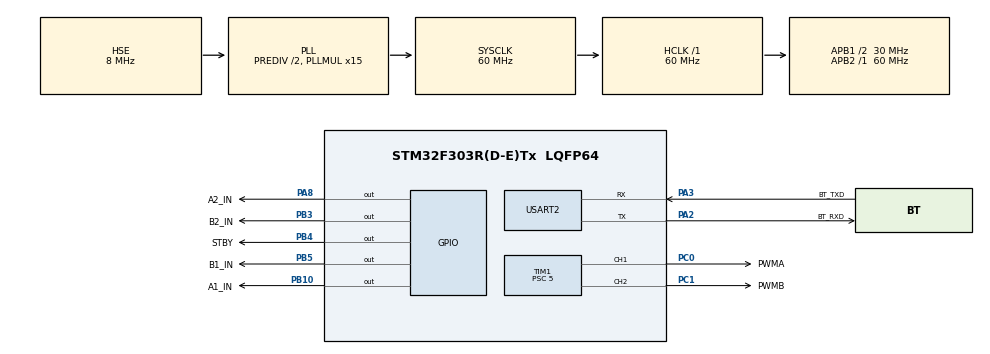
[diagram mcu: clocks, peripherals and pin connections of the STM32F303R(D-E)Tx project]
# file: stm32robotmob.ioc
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Mcu.Family=STM32F3
Mcu.Name=STM32F303R(D-E)Tx
Mcu.Package=LQFP64
NVIC.PriorityGroup=NVIC_PRIORITYGROUP_0
PA2.GPIO_Label=BT_RXD
PA2.Mode=Asynchronous
PA2.Signal=USART2_TX
PA3.GPIO_Label=BT_TXD
PA3.Mode=Asynchronous
PA3.Signal=USART2_RX
PA8.GPIO_Label=A2_IN
PA8.Signal=GPIO_Output
PB10.GPIO_Label=A1_IN
PB10.Signal=GPIO_Output
PB3.GPIO_Label=B2_IN
PB3.Signal=GPIO_Output
PB4.GPIO_Label=STBY
PB4.Signal=GPIO_Output
PB5.GPIO_Label=B1_IN
PB5.Signal=GPIO_Output
PC0.GPIO_Label=PWMA
PC0.Signal=S_TIM1_CH1
PC1.GPIO_Label=PWMB
PC1.Signal=S_TIM1_CH2
PF0-OSC_IN.Mode=HSE-External-Oscillator
PF0-OSC_IN.Signal=RCC_OSC_IN
PF1-OSC_OUT.Mode=HSE-External-Oscillator
PF1-OSC_OUT.Signal=RCC_OSC_OUT
ProjectManager.HeapSize=0x200
ProjectManager.StackSize=0x400
ProjectManager.TargetToolchain=STM32CubeIDE
RCC.AHBFreq_Value=60000000
RCC.APB1CLKDivider=RCC_HCLK_DIV2
RCC.APB1Freq_Value=30000000
RCC.APB1TimFreq_Value=60000000
RCC.APB2Freq_Value=60000000
RCC.APB2TimFreq_Value=60000000
RCC.CortexFreq_Value=60000000
RCC.HCLKFreq_Value=60000000
RCC.HSE_VALUE=8000000
RCC.HSI_VALUE=8000000
RCC.LSE_VALUE=32768
RCC.PLLDivider=RCC_PREDIV_DIV2
RCC.PLLM=8
RCC.PLLMUL=RCC_PLL_MUL15
RCC.PLLN=336
RCC.PLLP=RCC_PLLP_DIV4
RCC.PLLQ=7
RCC.PLLSourceVirtual=RCC_PLLSOURCE_HSE
RCC.RCC_PLLsource_Clock_Source_FROM_HSE=RCC_HSE_PREDIV_DIV2
RCC.SYSCLKFreq_VALUE=60000000
RCC.SYSCLKSourceVirtual=RCC_SYSCLKSOURCE_PLLCLK
RCC.USBFreq_Value=60000000
SH.S_TIM1_CH1.0=TIM1_CH1,PWM Generation1 CH1
SH.S_TIM1_CH2.0=TIM1_CH2,PWM Generation2 CH2
TIM1.AutoReloadPreload=TIM_AUTORELOAD_PRELOAD_ENABLE
TIM1.Channel-PWM\ Generation1\ CH1=TIM_CHANNEL_1
TIM1.Channel-PWM\ Generation2\ CH2=TIM_CHANNEL_2
TIM1.Period=59
TIM1.Prescaler=5
USART2.VirtualMode-Asynchronous=VM_ASYNC
board=NUCLEO-F303RE

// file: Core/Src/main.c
/* USER CODE BEGIN Header */
/**
  ******************************************************************************
  * @file           : main.c
  * @brief          : Main program body
  ******************************************************************************
  * @attention
  *
  * <h2><center>&copy; Copyright (c) 2022 STMicroelectronics.
  * All rights reserved.</center></h2>
  *
  * This software component is licensed by ST under BSD 3-Clause license,
  * the "License"; You may not use this file except in compliance with the
  * License. You may obtain a copy of the License at:
  *                        opensource.org/licenses/BSD-3-Clause
  *
  ******************************************************************************
  */
/* USER CODE END Header */
#include "main.h"
#include "tim.h"
#include "usart.h"
#include "gpio.h"

/* USER CODE BEGIN Includes */
#include "encontrol.h"
/* USER CODE END Includes */

void SystemClock_Config(void);

int main(void)
{

  /* MCU Configuration--------------------------------------------------------*/

  /* Reset of all peripherals, Initializes the Flash interface and the Systick. */
  HAL_Init();

  /* Configure the system clock */
  SystemClock_Config();

  /* Initialize all configured peripherals */
  MX_GPIO_Init();
  MX_TIM1_Init();
  MX_USART2_UART_Init();

  /* Infinite loop */
  while (1)
  {

  }
}

void SystemClock_Config(void)
{
  RCC_OscInitTypeDef RCC_OscInitStruct = {0};
  RCC_ClkInitTypeDef RCC_ClkInitStruct = {0};
  RCC_PeriphCLKInitTypeDef PeriphClkInit = {0};

  /** Initializes the RCC Oscillators according to the specified parameters
  * in the RCC_OscInitTypeDef structure.
  */
  RCC_OscInitStruct.OscillatorType = RCC_OSCILLATORTYPE_HSE;
  RCC_OscInitStruct.HSEState = RCC_HSE_ON;
  RCC_OscInitStruct.HSIState = RCC_HSI_ON;
  RCC_OscInitStruct.PLL.PLLState = RCC_PLL_ON;
  RCC_OscInitStruct.PLL.PLLSource = RCC_PLLSOURCE_HSE;
  RCC_OscInitStruct.PLL.PLLMUL = RCC_PLL_MUL15;
  RCC_OscInitStruct.PLL.PREDIV = RCC_PREDIV_DIV2;
  if (HAL_RCC_OscConfig(&RCC_OscInitStruct) != HAL_OK)
  {
    Error_Handler();
  }
  /** Initializes the CPU, AHB and APB buses clocks
  */
  RCC_ClkInitStruct.ClockType = RCC_CLOCKTYPE_HCLK|RCC_CLOCKTYPE_SYSCLK
                              |RCC_CLOCKTYPE_PCLK1|RCC_CLOCKTYPE_PCLK2;
  RCC_ClkInitStruct.SYSCLKSource = RCC_SYSCLKSOURCE_PLLCLK;
  RCC_ClkInitStruct.AHBCLKDivider = RCC_SYSCLK_DIV1;
  RCC_ClkInitStruct.APB1CLKDivider = RCC_HCLK_DIV2;
  RCC_ClkInitStruct.APB2CLKDivider = RCC_HCLK_DIV1;

  if (HAL_RCC_ClockConfig(&RCC_ClkInitStruct, FLASH_LATENCY_2) != HAL_OK)
  {
    Error_Handler();
  }
  PeriphClkInit.PeriphClockSelection = RCC_PERIPHCLK_USART2|RCC_PERIPHCLK_TIM1;
  PeriphClkInit.Usart2ClockSelection = RCC_USART2CLKSOURCE_PCLK1;
  PeriphClkInit.Tim1ClockSelection = RCC_TIM1CLK_HCLK;
  if (HAL_RCCEx_PeriphCLKConfig(&PeriphClkInit) != HAL_OK)
  {
    Error_Handler();
  }
}

void Error_Handler(void)
{
}

/************************ (C) COPYRIGHT STMicroelectronics *****END OF FILE****/
